# ATBTLC1000WLCSP register map
Vendor: Atmel Corp; Series: SAMB11; File version: TODO
CPU: CM0 r0p0, little endian, no MPU, no FPU, 2 interrupt priority bits
Address unit: 32 bits
Registers are 32-bit, read-write, reset 0x0 unless marked. A register's access mark holds for its fields unless they carry their own. Offsets are from the block's base; [hi:lo] are bit positions; {n}, {i} and the like mark numbered series.

## UART0 — UART Controller
Base 0x40004000
Same registers: UART1 0x40005000
0x00 TRANSMIT_DATA 8-bit wo — Writes one byte to UART Transmit Data FIFO.
  [7:0] TX_BYTE — Writes data in transmit FIFO. If byte length is set to 7, the MSB should be set to 0.
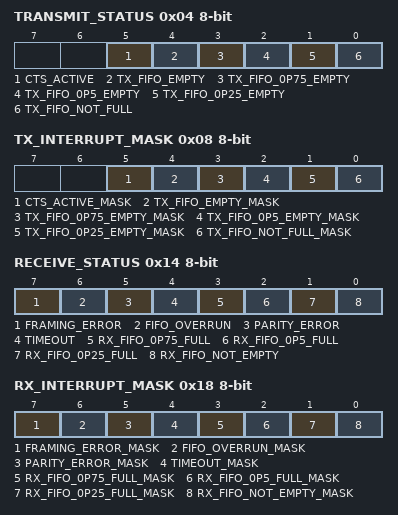
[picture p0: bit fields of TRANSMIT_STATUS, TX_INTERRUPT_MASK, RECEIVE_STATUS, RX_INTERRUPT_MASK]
0x04 TRANSMIT_STATUS 8-bit ro — Status of the UART transmitter. Each field can generate an interrupt if corresponding bit in the Tx interrupt mask register is set.
  [5] CTS_ACTIVE — Active High indication when flow control signal "cts" is active. Unaffected by cts enable bit in config register.
  [4] TX_FIFO_EMPTY — Active High indication when Tx FIFO is Empty and has no more character to transmit
  [3] TX_FIFO_0P75_EMPTY — Active High indication when Tx FIFO is at least three quarters empty. Reset when more.
  [2] TX_FIFO_0P5_EMPTY — Active High indication when Tx FIFO is at least half empty. Reset when more.
  [1] TX_FIFO_0P25_EMPTY — Active High indication when Tx FIFO is at least quarter empty. Reset when more.
  [0] TX_FIFO_NOT_FULL — Active High indication when Tx FIFO can still accepts at least one more character. 0: TX FIFO Full. 1: TX FIFO not Full.
0x08 TX_INTERRUPT_MASK 8-bit — Enable or Disable the generation of interrupts by the tx_status register.
  [5] CTS_ACTIVE_MASK — Active High Enable of cts_active interrupt
  [4] TX_FIFO_EMPTY_MASK — Active High Enable of tx_fifo_empty interrupt
  [3] TX_FIFO_0P75_EMPTY_MASK — Active High Enable of tx_fifo_0p75_empty interrupt
  [2] TX_FIFO_0P5_EMPTY_MASK — Active High Enable of tx_fifo_0p5_empty interrupt
  [1] TX_FIFO_0P25_EMPTY_MASK — Active High Enable of tx_fifo_0p25_empty interrupt
  [0] TX_FIFO_NOT_FULL_MASK — Active High Enable of tx_fifo_not_full interrupt
0x10 RECEIVE_DATA 8-bit ro — Read one byte from UART Receive Data FIFO.
  [7:0] RX_BYTE — Oldest data in receive FIFO. If byte length is set to 7, the MSB is set to 0.
0x14 RECEIVE_STATUS 8-bit ro — Status of the UART receiver. Each field can generate an interrupt if corresponding bit in the Rx interrupt mask register is set.
  [7] FRAMING_ERROR — Active High indication when no stop bit is detected. Reset by reading the status register.
  [6] FIFO_OVERRUN — Active High indication when character is received but FIFO is full. Reset by reading the status register.
  [5] PARITY_ERROR — Active High indication when a receive parity error is detected. Reset by reading the status register.
  [4] TIMEOUT — Active High indication when the timeout set in the rx_timeout register has elapsed since the last interaction with the receiver. Reset by reading the status register.
  [3] RX_FIFO_0P75_FULL — Active High indication when FIFO is at least three quarters full. Reset when less.
  [2] RX_FIFO_0P5_FULL — Active High indication when FIFO is at least half full. Reset when less.
  [1] RX_FIFO_0P25_FULL — Active High indication when FIFO is at least quarter full. Reset when less.
  [0] RX_FIFO_NOT_EMPTY — Active High indication when data is available in Rx FIFO. 0: RX FIFO Empty. 1: RX FIFO contains at least one byte of data.
0x18 RX_INTERRUPT_MASK 8-bit — Enable or Disable the generation of interrupts by the rx_status register.
  [7] FRAMING_ERROR_MASK — Active High Enable of framing error interrupt
  [6] FIFO_OVERRUN_MASK — Active High Enable of FIFO overrun interrupt
  [5] PARITY_ERROR_MASK — Active High Enable of parity error interrupt
  [4] TIMEOUT_MASK — Active High Enable of timeout interrupt
  [3] RX_FIFO_0P75_FULL_MASK — Active High Enable of rx_fifo_0p75_full interrupt
  [2] RX_FIFO_0P5_FULL_MASK — Active High Enable of rx_fifo_0p5_full interrupt
  [1] RX_FIFO_0P25_FULL_MASK — Active High Enable of rx_fifo_0p25_full interrupt
  [0] RX_FIFO_NOT_EMPTY_MASK — Active High Enable of rx_fifo_not_empty interrupt
0x1C RECEIVE_TIMEOUT 8-bit — Timeout counter configuration.
  [7:0] TIMEOUT_VALUE — Timeout counter reload value, after status register is read or character received. Counter decrements at baud rate clock.
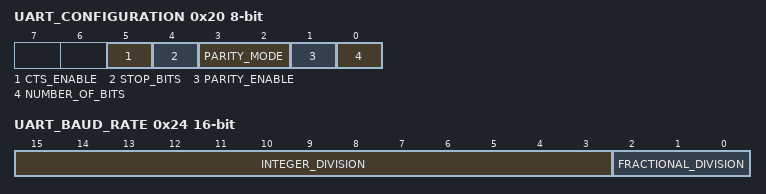
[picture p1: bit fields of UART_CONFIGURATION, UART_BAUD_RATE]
0x20 UART_CONFIGURATION 8-bit — UART Operation Configuration Register, for both Rx and Tx.
  [5] CTS_ENABLE — Active High Flow Control Enable. When enabled, transmission starts when cts signal is asserted
    0=Disable-Transmission starts only when cts signal is asserted; 1=Enable-Transmission starts regardless of cts signal
  [4] STOP_BITS — Number of stop bits
    0=One Bit; 1=Two Bits
  [3:2] PARITY_MODE — Parity Mode Select
    0=Even Parity; 1=Odd Parity; 2=Parity bit is space; 3=Parity bit is mark
  [1] PARITY_ENABLE — Active High parity checking and generation enable
    0=Disable; 1=Enable
  [0] NUMBER_OF_BITS — Number of bits per character, not including parity
    0=8 bits; 1=7 bits
0x24 UART_BAUD_RATE 16-bit — Baud Rate Control Register. Bits 15:3 specify the integral division of the clock (divide by n), and bit 2:0 specify the fractional division.
  [15:3] INTEGER_DIVISION — Integral Division Part. Must be at least set to 2.
  [2:0] FRACTIONAL_DIVISION — Fractional Division Part. If non-zero, the integer part must be at least set to 3.
0x28 UART_CLOCK_SOURCE 8-bit — Selects Source of UART Clock
  [1:0] CLOCK_SELECT — Selects one of the four possible clock sources.
    {v}=Clock input {v} (v=0..3)
